# RZT2L register map
Vendor: Renesas Electronics Corporation; Series: RZT; File version: 1.20.00
CPU: other r0p0, little endian, MPU, no FPU, VTOR, 4 interrupt priority bits, 624 interrupts
Registers are 32-bit, read-write, reset 0x0 unless marked. A register's access mark holds for its fields unless they carry their own. Offsets are from the block's base; [hi:lo] are bit positions; 'fields as' and 'values as' point back to an identical list.

## TFU — Trigonometric Function Unit
Base 0x90003000
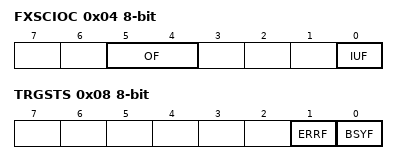
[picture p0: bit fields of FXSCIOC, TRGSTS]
0x04 FXSCIOC 8-bit — Fixed-point Sine Cosine Input/Output Setting Register
  [5:4] OF — Output format setting
    0=Q1.31; 1=Q2.30; 2=Q3.29; 3=Setting prohibited
  [0] IUF — Input unit and format setting
    0=unit, format = turn, Q1.31; 1=unit, format = radian, Q3.29
0x05 FXATIOC 8-bit — Fixed-point Arctangent hypot_k Input/Output Setting Register
  [4] OUF — Output unit and format setting
    0=unit, format = turn, Q1.31; 1=unit, format = radian, Q3.29
0x08 TRGSTS 8-bit — Trigonometric Status Register
  [1] ERRF — Input error flag
    0=No input error occurred; 1=Input error occurred
  [0] BSYF — Calculation in progress flag
    0=No calculating; 1=Calculating
0x10 FPSCDT0 — Floating-point Sine Cosine Data Register 0
0x14 FPSCDT1 — Floating-point Sine Cosine Data Register 1
0x18 FPATDT0 — Floating-point Arctangent hypot_k Data Register 0
0x1C FPATDT1 — Floating-point Arctangent hypot_k Data Register 1
0x20 FXSCDT0 — Fixed-point Sine Cosine Data Register 0
0x24 FXSCDT1 — Fixed-point Sine Cosine Data Register 1
0x28 FXATDT0 — Fixed-point Arctangent hypot_k Data Register 0
0x2C FXATDT1 — Fixed-point Arctangent hypot_k Data Register 1
0x30 DTSR0 — Data Save Restore Register 0
0x34 DTSR1 — Data Save Restore Register 1

## POEG0 — GPT Port Output Enable 0
Base 0x90006000
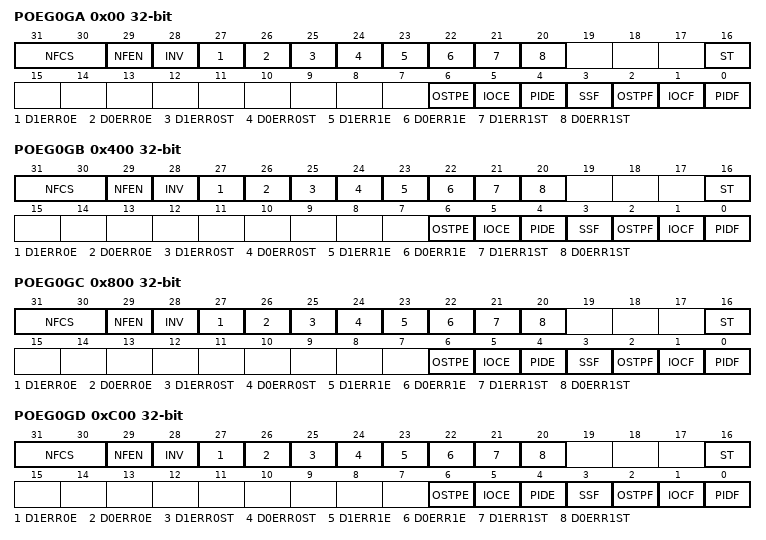
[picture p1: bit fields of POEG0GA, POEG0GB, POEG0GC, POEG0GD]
0x00 POEG0GA — POEG0 Group A Setting Register
  [31:30] NFCS — Noise filter Clock Select
    0=Samples the input level of GTETRGn pin three times per PCLKH clock; 1=Samples the input level of GTETRGn pin three times per PCLKH/8 clock; 2=Samples the input level of GTETRGn pin three times per PCLKH/32 clock; 3=Samples the input level of GTETRGn pin three times per PCLKH/128 clock
  [29] NFEN — Noise filter Enable
    0=Digital noise filter on the GTETRGn pin is disabled; 1=Digital noise filter on the GTETRGn pin is enabled
  [28] INV — GTETRGn Input Inverting
    0=Input on the GTETRGn pin is not inverted; 1=Input on the GTETRGn pin is inverted
  [27] D1ERR0E — Permit output disabled by DSMIF1 error 0 detection
    0=Disable; 1=Not disabled
  [26] D0ERR0E — Permit output disabled by DSMIF0 error 0 detection
    0=Disable; 1=Not disabled
  [25] D1ERR0ST ro — DSMIF1 error 0 status
    0=Not error detect; 1=Error detect
  [24] D0ERR0ST ro — DSMIF0 error 0 status
    0=Not error detect; 1=Error detect
  [23] D1ERR1E — Permit output disabled by DSMIF1 error 1 detection
    0=Disable; 1=Not disabled
  [22] D0ERR1E — Permit output disabled by DSMIF0 error 1 detection
    0=Disable; 1=Not disabled
  [21] D1ERR1ST ro — DSMIF1 error 1 status
    0=Not error detect; 1=Error detect
  [20] D0ERR1ST ro — DSMIF0 error 1 status
    0=Not error detect; 1=Error detect
  [16] ST ro — GTETRGn Input Status Flag
    0=GTETRGn input after filtering was 0; 1=GTETRGn input after filtering was 1
  [6] OSTPE — Enable Stopping Output on Stopping of Oscillation
    0=Detection of stopping of oscillation is disabled; 1=Detection of stopping of oscillation is enabled
  [5] IOCE — GPT Output Stop Request Enable
    0=Detection of stopping of output from the GPT is disabled; 1=Detection of stopping of output from the GPT is enabled
  [4] PIDE — Port Input Detection Enable
    0=Detection of input levels on the corresponding GTETRGn pin is disabled; 1=Detection of input levels on the corresponding GTETRGn pin is enabled
  [3] SSF — Software Stop Flag
    0=Software has not stopped output; 1=Software has stopped output
  [2] OSTPF — Oscillation Stop Detection Flag
    0=Stopping of oscillation was not detected; 1=Stopping of oscillation was detected
  [1] IOCF — GPT Output Stop Request Detection Flag
    0=Stopping of GPT output was not detected; 1=Stopping of GPT output was detected
  [0] PIDF — Port Input Detection Flag
    0=The selected input level was not detected on the GTETRGn pin; 1=The selected input level was detected on the GTETRGn pin
0x400 POEG0GB — POEG0 Group B Setting Register
  fields as POEG0GA
0x800 POEG0GC — POEG0 Group C Setting Register
  fields as POEG0GA
0xC00 POEG0GD — POEG0 Group D Setting Register
  fields as POEG0GA
